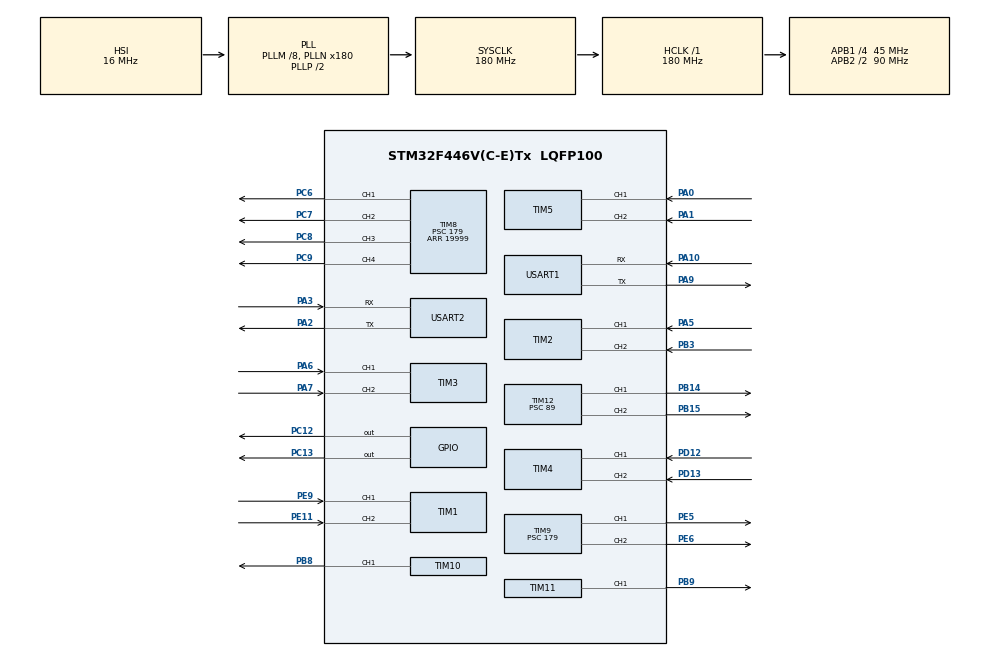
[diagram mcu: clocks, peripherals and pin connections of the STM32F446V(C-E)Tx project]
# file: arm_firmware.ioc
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Dma.Request0=USART1_RX
Dma.USART1_RX.0.Direction=DMA_PERIPH_TO_MEMORY
Dma.USART1_RX.0.FIFOMode=DMA_FIFOMODE_DISABLE
Dma.USART1_RX.0.Instance=DMA2_Stream2
Dma.USART1_RX.0.MemDataAlignment=DMA_MDATAALIGN_BYTE
Dma.USART1_RX.0.MemInc=DMA_MINC_ENABLE
Dma.USART1_RX.0.Mode=DMA_CIRCULAR
Dma.USART1_RX.0.PeriphDataAlignment=DMA_PDATAALIGN_BYTE
Dma.USART1_RX.0.PeriphInc=DMA_PINC_DISABLE
Dma.USART1_RX.0.Priority=DMA_PRIORITY_LOW
Mcu.Family=STM32F4
Mcu.Name=STM32F446V(C-E)Tx
Mcu.Package=LQFP100
NVIC.DMA2_Stream2_IRQn=true\:0\:0\:false\:false\:true\:false\:true\:true
NVIC.PriorityGroup=NVIC_PRIORITYGROUP_4
NVIC.USART1_IRQn=true\:0\:0\:false\:false\:true\:true\:true\:true
PA0-WKUP.Signal=S_TIM5_CH1
PA1.Signal=S_TIM5_CH2
PA10.Mode=Asynchronous
PA10.Signal=USART1_RX
PA13.Mode=Serial_Wire
PA13.Signal=SYS_JTMS-SWDIO
PA14.Mode=Serial_Wire
PA14.Signal=SYS_JTCK-SWCLK
PA2.Mode=Asynchronous
PA2.Signal=USART2_TX
PA3.Mode=Asynchronous
PA3.Signal=USART2_RX
PA5.Signal=S_TIM2_CH1_ETR
PA6.Signal=S_TIM3_CH1
PA7.Signal=S_TIM3_CH2
PA9.Mode=Asynchronous
PA9.Signal=USART1_TX
PB14.Signal=S_TIM12_CH1
PB15.Signal=S_TIM12_CH2
PB3.Signal=S_TIM2_CH2
PB8.Signal=S_TIM10_CH1
PB9.Signal=S_TIM11_CH1
PC12.Signal=GPIO_Output
PC13.Signal=GPIO_Output
PC6.Signal=S_TIM8_CH1
PC7.Signal=S_TIM8_CH2
PC8.Signal=S_TIM8_CH3
PC9.Signal=S_TIM8_CH4
PD12.Signal=S_TIM4_CH1
PD13.Signal=S_TIM4_CH2
PE11.Signal=S_TIM1_CH2
PE5.Signal=S_TIM9_CH1
PE6.Signal=S_TIM9_CH2
PE9.Signal=S_TIM1_CH1
PH0-OSC_IN.Mode=HSE-External-Oscillator
PH0-OSC_IN.Signal=RCC_OSC_IN
PH1-OSC_OUT.Mode=HSE-External-Oscillator
PH1-OSC_OUT.Signal=RCC_OSC_OUT
ProjectManager.HeapSize=0x200
ProjectManager.StackSize=0x400
ProjectManager.TargetToolchain=STM32CubeIDE
RCC.AHBFreq_Value=180000000
RCC.APB1CLKDivider=RCC_HCLK_DIV4
RCC.APB1Freq_Value=45000000
RCC.APB1TimFreq_Value=90000000
RCC.APB2CLKDivider=RCC_HCLK_DIV2
RCC.APB2Freq_Value=90000000
RCC.APB2TimFreq_Value=180000000
RCC.CortexFreq_Value=180000000
RCC.HCLKFreq_Value=180000000
RCC.PLLM=8
RCC.PLLN=180
RCC.SYSCLKFreq_VALUE=180000000
RCC.SYSCLKSource=RCC_SYSCLKSOURCE_PLLCLK
RCC.USBFreq_Value=180000000
RCC.VCOOutputFreq_Value=360000000
SH.S_TIM10_CH1.0=TIM10_CH1,PWM Generation1 CH1
SH.S_TIM11_CH1.0=TIM11_CH1,PWM Generation1 CH1
SH.S_TIM12_CH1.0=TIM12_CH1,PWM Generation1 CH1
SH.S_TIM12_CH2.0=TIM12_CH2,PWM Generation2 CH2
SH.S_TIM1_CH1.0=TIM1_CH1,Encoder_Interface
SH.S_TIM1_CH2.0=TIM1_CH2,Encoder_Interface
SH.S_TIM2_CH1_ETR.0=TIM2_CH1,Encoder_Interface
SH.S_TIM2_CH2.0=TIM2_CH2,Encoder_Interface
SH.S_TIM3_CH1.0=TIM3_CH1,Encoder_Interface
SH.S_TIM3_CH2.0=TIM3_CH2,Encoder_Interface
SH.S_TIM4_CH1.0=TIM4_CH1,Encoder_Interface
SH.S_TIM4_CH2.0=TIM4_CH2,Encoder_Interface
SH.S_TIM5_CH1.0=TIM5_CH1,Encoder_Interface
SH.S_TIM5_CH2.0=TIM5_CH2,Encoder_Interface
SH.S_TIM8_CH1.0=TIM8_CH1,PWM Generation1 CH1
SH.S_TIM8_CH2.0=TIM8_CH2,PWM Generation2 CH2
SH.S_TIM8_CH3.0=TIM8_CH3,PWM Generation3 CH3
SH.S_TIM8_CH4.0=TIM8_CH4,PWM Generation4 CH4
SH.S_TIM9_CH1.0=TIM9_CH1,PWM Generation1 CH1
SH.S_TIM9_CH2.0=TIM9_CH2,PWM Generation2 CH2
TIM1.EncoderMode=TIM_ENCODERMODE_TI12
TIM1.IC1Filter=8
TIM1.IC1Polarity=TIM_ICPOLARITY_FALLING
TIM1.IC2Filter=8
TIM10.Channel=TIM_CHANNEL_1
TIM10.Period=19999
TIM10.Prescaler=179
TIM11.Channel=TIM_CHANNEL_1
TIM11.Period=19999
TIM11.Prescaler=179
TIM12.Channel-PWM\ Generation1\ CH1=TIM_CHANNEL_1
TIM12.Channel-PWM\ Generation2\ CH2=TIM_CHANNEL_2
TIM12.Period=19999
TIM12.Prescaler=89
TIM2.EncoderMode=TIM_ENCODERMODE_TI12
TIM2.IC1Filter=8
TIM2.IC1Polarity=TIM_ICPOLARITY_FALLING
TIM2.IC2Filter=8
TIM3.EncoderMode=TIM_ENCODERMODE_TI12
TIM3.IC1Filter=8
TIM3.IC1Polarity=TIM_ICPOLARITY_FALLING
TIM3.IC2Filter=8
TIM4.EncoderMode=TIM_ENCODERMODE_TI12
TIM4.IC1Filter=8
TIM4.IC1Polarity=TIM_ICPOLARITY_FALLING
TIM4.IC2Filter=8
TIM5.EncoderMode=TIM_ENCODERMODE_TI12
TIM5.IC1Filter=8
TIM5.IC1Polarity=TIM_ICPOLARITY_FALLING
TIM5.IC2Filter=8
TIM8.Channel-PWM\ Generation1\ CH1=TIM_CHANNEL_1
TIM8.Channel-PWM\ Generation2\ CH2=TIM_CHANNEL_2
TIM8.Channel-PWM\ Generation3\ CH3=TIM_CHANNEL_3
TIM8.Channel-PWM\ Generation4\ CH4=TIM_CHANNEL_4
TIM8.Period=19999
TIM8.Prescaler=179
TIM9.Channel-PWM\ Generation1\ CH1=TIM_CHANNEL_1
TIM9.Channel-PWM\ Generation2\ CH2=TIM_CHANNEL_2
TIM9.Period=19999
TIM9.Prescaler=179
USART1.VirtualMode=VM_ASYNC
USART2.VirtualMode=VM_ASYNC
VP_TIM10_VS_ClockSourceINT.Mode=Enable_Timer
VP_TIM11_VS_ClockSourceINT.Mode=Enable_Timer
board=custom

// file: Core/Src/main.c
/* USER CODE BEGIN Header */
/**
  ******************************************************************************
  * @file           : main.c
  * @brief          : Main program body
  ******************************************************************************
  * @attention
  *
  * Copyright (c) 2026 STMicroelectronics.
  * All rights reserved.
  *
  * This software is licensed under terms that can be found in the LICENSE file
  * in the root directory of this software component.
  * If no LICENSE file comes with this software, it is provided AS-IS.
  *
  ******************************************************************************
  */
/* USER CODE END Header */
#include "main.h"

/* USER CODE BEGIN Includes */
#include "servo.h"
#include "encoder.h"
#include "pid.h"
#include "joint_control.h"
/* USER CODE END Includes */

TIM_HandleTypeDef htim1;
TIM_HandleTypeDef htim2;
TIM_HandleTypeDef htim3;
TIM_HandleTypeDef htim4;
TIM_HandleTypeDef htim5;
TIM_HandleTypeDef htim8;
TIM_HandleTypeDef htim9;
TIM_HandleTypeDef htim10;
TIM_HandleTypeDef htim11;
TIM_HandleTypeDef htim12;

UART_HandleTypeDef huart1;
UART_HandleTypeDef huart2;
DMA_HandleTypeDef hdma_usart1_rx;

void SystemClock_Config(void);
static void MX_GPIO_Init(void);
static void MX_DMA_Init(void);
static void MX_TIM1_Init(void);
static void MX_TIM2_Init(void);
static void MX_TIM3_Init(void);
static void MX_TIM4_Init(void);
static void MX_TIM5_Init(void);
static void MX_TIM8_Init(void);
static void MX_TIM9_Init(void);
static void MX_TIM12_Init(void);
static void MX_TIM10_Init(void);
static void MX_TIM11_Init(void);
static void MX_USART1_UART_Init(void);
static void MX_USART2_UART_Init(void);

int main(void)
{

  /* MCU Configuration--------------------------------------------------------*/

  /* Reset of all peripherals, Initializes the Flash interface and the Systick. */
  HAL_Init();

  /* Configure the system clock */
  SystemClock_Config();

  /* Initialize all configured peripherals */
  MX_GPIO_Init();
  MX_DMA_Init();
  MX_TIM1_Init();
  MX_TIM2_Init();
  MX_TIM3_Init();
  MX_TIM4_Init();
  MX_TIM5_Init();
  MX_TIM8_Init();
  MX_TIM9_Init();
  MX_TIM12_Init();
  MX_TIM10_Init();
  MX_TIM11_Init();
  MX_USART1_UART_Init();
  MX_USART2_UART_Init();
  /* USER CODE BEGIN 2 */
  Servo_Init();
  Encoder_Init();
  JointControl_Init();
  /* USER CODE END 2 */

  /* Infinite loop */
  while (1)
  {

    /* USER CODE BEGIN 3 */
    // JointControl_Update(0.010f);
    HAL_GPIO_TogglePin(GPIOC, GPIO_PIN_12);
    HAL_GPIO_TogglePin(GPIOC, GPIO_PIN_13);
     HAL_Delay(500);

    // Call test pattern for PWM output testing
//    Servo_Test_Patterns();
  }
  /* USER CODE END 3 */
}

void SystemClock_Config(void)
{
  RCC_OscInitTypeDef RCC_OscInitStruct = {0};
  RCC_ClkInitTypeDef RCC_ClkInitStruct = {0};

  /** Configure the main internal regulator output voltage
  */
  __HAL_RCC_PWR_CLK_ENABLE();
  __HAL_PWR_VOLTAGESCALING_CONFIG(PWR_REGULATOR_VOLTAGE_SCALE1);

  /** Initializes the RCC Oscillators according to the specified parameters
  * in the RCC_OscInitTypeDef structure.
  */
  RCC_OscInitStruct.OscillatorType = RCC_OSCILLATORTYPE_HSI;
  RCC_OscInitStruct.HSIState = RCC_HSI_ON;
  RCC_OscInitStruct.HSICalibrationValue = RCC_HSICALIBRATION_DEFAULT;
  RCC_OscInitStruct.PLL.PLLState = RCC_PLL_ON;
  RCC_OscInitStruct.PLL.PLLSource = RCC_PLLSOURCE_HSI;
  RCC_OscInitStruct.PLL.PLLM = 8;
  RCC_OscInitStruct.PLL.PLLN = 180;
  RCC_OscInitStruct.PLL.PLLP = RCC_PLLP_DIV2;
  RCC_OscInitStruct.PLL.PLLQ = 2;
  RCC_OscInitStruct.PLL.PLLR = 2;
  if (HAL_RCC_OscConfig(&RCC_OscInitStruct) != HAL_OK)
  {
    Error_Handler();
  }

  /** Activate the Over-Drive mode
  */
  if (HAL_PWREx_EnableOverDrive() != HAL_OK)
  {
    Error_Handler();
  }

  /** Initializes the CPU, AHB and APB buses clocks
  */
  RCC_ClkInitStruct.ClockType = RCC_CLOCKTYPE_HCLK|RCC_CLOCKTYPE_SYSCLK
                              |RCC_CLOCKTYPE_PCLK1|RCC_CLOCKTYPE_PCLK2;
  RCC_ClkInitStruct.SYSCLKSource = RCC_SYSCLKSOURCE_PLLCLK;
  RCC_ClkInitStruct.AHBCLKDivider = RCC_SYSCLK_DIV1;
  RCC_ClkInitStruct.APB1CLKDivider = RCC_HCLK_DIV4;
  RCC_ClkInitStruct.APB2CLKDivider = RCC_HCLK_DIV2;

  if (HAL_RCC_ClockConfig(&RCC_ClkInitStruct, FLASH_LATENCY_5) != HAL_OK)
  {
    Error_Handler();
  }
}

static void MX_TIM1_Init(void)
{

  TIM_Encoder_InitTypeDef sConfig = {0};
  TIM_MasterConfigTypeDef sMasterConfig = {0};

  htim1.Instance = TIM1;
  htim1.Init.Prescaler = 0;
  htim1.Init.CounterMode = TIM_COUNTERMODE_UP;
  htim1.Init.Period = 65535;
  htim1.Init.ClockDivision = TIM_CLOCKDIVISION_DIV1;
  htim1.Init.RepetitionCounter = 0;
  htim1.Init.AutoReloadPreload = TIM_AUTORELOAD_PRELOAD_DISABLE;
  sConfig.EncoderMode = TIM_ENCODERMODE_TI12;
  sConfig.IC1Polarity = TIM_ICPOLARITY_FALLING;
  sConfig.IC1Selection = TIM_ICSELECTION_DIRECTTI;
  sConfig.IC1Prescaler = TIM_ICPSC_DIV1;
  sConfig.IC1Filter = 8;
  sConfig.IC2Polarity = TIM_ICPOLARITY_RISING;
  sConfig.IC2Selection = TIM_ICSELECTION_DIRECTTI;
  sConfig.IC2Prescaler = TIM_ICPSC_DIV1;
  sConfig.IC2Filter = 8;
  if (HAL_TIM_Encoder_Init(&htim1, &sConfig) != HAL_OK)
  {
    Error_Handler();
  }
  sMasterConfig.MasterOutputTrigger = TIM_TRGO_RESET;
  sMasterConfig.MasterSlaveMode = TIM_MASTERSLAVEMODE_DISABLE;
  if (HAL_TIMEx_MasterConfigSynchronization(&htim1, &sMasterConfig) != HAL_OK)
  {
    Error_Handler();
  }

}

static void MX_TIM2_Init(void)
{

  TIM_Encoder_InitTypeDef sConfig = {0};
  TIM_MasterConfigTypeDef sMasterConfig = {0};

  htim2.Instance = TIM2;
  htim2.Init.Prescaler = 0;
  htim2.Init.CounterMode = TIM_COUNTERMODE_UP;
  htim2.Init.Period = 4294967295;
  htim2.Init.ClockDivision = TIM_CLOCKDIVISION_DIV1;
  htim2.Init.AutoReloadPreload = TIM_AUTORELOAD_PRELOAD_DISABLE;
  sConfig.EncoderMode = TIM_ENCODERMODE_TI12;
  sConfig.IC1Polarity = TIM_ICPOLARITY_FALLING;
  sConfig.IC1Selection = TIM_ICSELECTION_DIRECTTI;
  sConfig.IC1Prescaler = TIM_ICPSC_DIV1;
  sConfig.IC1Filter = 8;
  sConfig.IC2Polarity = TIM_ICPOLARITY_RISING;
  sConfig.IC2Selection = TIM_ICSELECTION_DIRECTTI;
  sConfig.IC2Prescaler = TIM_ICPSC_DIV1;
  sConfig.IC2Filter = 8;
  if (HAL_TIM_Encoder_Init(&htim2, &sConfig) != HAL_OK)
  {
    Error_Handler();
  }
  sMasterConfig.MasterOutputTrigger = TIM_TRGO_RESET;
  sMasterConfig.MasterSlaveMode = TIM_MASTERSLAVEMODE_DISABLE;
  if (HAL_TIMEx_MasterConfigSynchronization(&htim2, &sMasterConfig) != HAL_OK)
  {
    Error_Handler();
  }

}

static void MX_TIM3_Init(void)
{

  TIM_Encoder_InitTypeDef sConfig = {0};
  TIM_MasterConfigTypeDef sMasterConfig = {0};

  htim3.Instance = TIM3;
  htim3.Init.Prescaler = 0;
  htim3.Init.CounterMode = TIM_COUNTERMODE_UP;
  htim3.Init.Period = 65535;
  htim3.Init.ClockDivision = TIM_CLOCKDIVISION_DIV1;
  htim3.Init.AutoReloadPreload = TIM_AUTORELOAD_PRELOAD_DISABLE;
  sConfig.EncoderMode = TIM_ENCODERMODE_TI12;
  sConfig.IC1Polarity = TIM_ICPOLARITY_FALLING;
  sConfig.IC1Selection = TIM_ICSELECTION_DIRECTTI;
  sConfig.IC1Prescaler = TIM_ICPSC_DIV1;
  sConfig.IC1Filter = 8;
  sConfig.IC2Polarity = TIM_ICPOLARITY_RISING;
  sConfig.IC2Selection = TIM_ICSELECTION_DIRECTTI;
  sConfig.IC2Prescaler = TIM_ICPSC_DIV1;
  sConfig.IC2Filter = 8;
  if (HAL_TIM_Encoder_Init(&htim3, &sConfig) != HAL_OK)
  {
    Error_Handler();
  }
  sMasterConfig.MasterOutputTrigger = TIM_TRGO_RESET;
  sMasterConfig.MasterSlaveMode = TIM_MASTERSLAVEMODE_DISABLE;
  if (HAL_TIMEx_MasterConfigSynchronization(&htim3, &sMasterConfig) != HAL_OK)
  {
    Error_Handler();
  }

}

static void MX_TIM4_Init(void)
{

  TIM_Encoder_InitTypeDef sConfig = {0};
  TIM_MasterConfigTypeDef sMasterConfig = {0};

  htim4.Instance = TIM4;
  htim4.Init.Prescaler = 0;
  htim4.Init.CounterMode = TIM_COUNTERMODE_UP;
  htim4.Init.Period = 65535;
  htim4.Init.ClockDivision = TIM_CLOCKDIVISION_DIV1;
  htim4.Init.AutoReloadPreload = TIM_AUTORELOAD_PRELOAD_DISABLE;
  sConfig.EncoderMode = TIM_ENCODERMODE_TI12;
  sConfig.IC1Polarity = TIM_ICPOLARITY_FALLING;
  sConfig.IC1Selection = TIM_ICSELECTION_DIRECTTI;
  sConfig.IC1Prescaler = TIM_ICPSC_DIV1;
  sConfig.IC1Filter = 8;
  sConfig.IC2Polarity = TIM_ICPOLARITY_RISING;
  sConfig.IC2Selection = TIM_ICSELECTION_DIRECTTI;
  sConfig.IC2Prescaler = TIM_ICPSC_DIV1;
  sConfig.IC2Filter = 8;
  if (HAL_TIM_Encoder_Init(&htim4, &sConfig) != HAL_OK)
  {
    Error_Handler();
  }
  sMasterConfig.MasterOutputTrigger = TIM_TRGO_RESET;
  sMasterConfig.MasterSlaveMode = TIM_MASTERSLAVEMODE_DISABLE;
  if (HAL_TIMEx_MasterConfigSynchronization(&htim4, &sMasterConfig) != HAL_OK)
  {
    Error_Handler();
  }

}

static void MX_TIM5_Init(void)
{

  TIM_Encoder_InitTypeDef sConfig = {0};
  TIM_MasterConfigTypeDef sMasterConfig = {0};

  htim5.Instance = TIM5;
  htim5.Init.Prescaler = 0;
  htim5.Init.CounterMode = TIM_COUNTERMODE_UP;
  htim5.Init.Period = 4294967295;
  htim5.Init.ClockDivision = TIM_CLOCKDIVISION_DIV1;
  htim5.Init.AutoReloadPreload = TIM_AUTORELOAD_PRELOAD_DISABLE;
  sConfig.EncoderMode = TIM_ENCODERMODE_TI12;
  sConfig.IC1Polarity = TIM_ICPOLARITY_FALLING;
  sConfig.IC1Selection = TIM_ICSELECTION_DIRECTTI;
  sConfig.IC1Prescaler = TIM_ICPSC_DIV1;
  sConfig.IC1Filter = 8;
  sConfig.IC2Polarity = TIM_ICPOLARITY_RISING;
  sConfig.IC2Selection = TIM_ICSELECTION_DIRECTTI;
  sConfig.IC2Prescaler = TIM_ICPSC_DIV1;
  sConfig.IC2Filter = 8;
  if (HAL_TIM_Encoder_Init(&htim5, &sConfig) != HAL_OK)
  {
    Error_Handler();
  }
  sMasterConfig.MasterOutputTrigger = TIM_TRGO_RESET;
  sMasterConfig.MasterSlaveMode = TIM_MASTERSLAVEMODE_DISABLE;
  if (HAL_TIMEx_MasterConfigSynchronization(&htim5, &sMasterConfig) != HAL_OK)
  {
    Error_Handler();
  }

}

static void MX_TIM8_Init(void)
{

  TIM_MasterConfigTypeDef sMasterConfig = {0};
  TIM_OC_InitTypeDef sConfigOC = {0};
  TIM_BreakDeadTimeConfigTypeDef sBreakDeadTimeConfig = {0};

  htim8.Instance = TIM8;
  htim8.Init.Prescaler = 179;
  htim8.Init.CounterMode = TIM_COUNTERMODE_UP;
  htim8.Init.Period = 19999;
  htim8.Init.ClockDivision = TIM_CLOCKDIVISION_DIV1;
  htim8.Init.RepetitionCounter = 0;
  htim8.Init.AutoReloadPreload = TIM_AUTORELOAD_PRELOAD_DISABLE;
  if (HAL_TIM_PWM_Init(&htim8) != HAL_OK)
  {
    Error_Handler();
  }
  sMasterConfig.MasterOutputTrigger = TIM_TRGO_RESET;
  sMasterConfig.MasterSlaveMode = TIM_MASTERSLAVEMODE_DISABLE;
  if (HAL_TIMEx_MasterConfigSynchronization(&htim8, &sMasterConfig) != HAL_OK)
  {
    Error_Handler();
  }
  sConfigOC.OCMode = TIM_OCMODE_PWM1;
  sConfigOC.Pulse = 0;
  sConfigOC.OCPolarity = TIM_OCPOLARITY_HIGH;
  sConfigOC.OCNPolarity = TIM_OCNPOLARITY_HIGH;
  sConfigOC.OCFastMode = TIM_OCFAST_DISABLE;
  sConfigOC.OCIdleState = TIM_OCIDLESTATE_RESET;
  sConfigOC.OCNIdleState = TIM_OCNIDLESTATE_RESET;
  if (HAL_TIM_PWM_ConfigChannel(&htim8, &sConfigOC, TIM_CHANNEL_1) != HAL_OK)
  {
    Error_Handler();
  }
  if (HAL_TIM_PWM_ConfigChannel(&htim8, &sConfigOC, TIM_CHANNEL_2) != HAL_OK)
  {
    Error_Handler();
  }
  if (HAL_TIM_PWM_ConfigChannel(&htim8, &sConfigOC, TIM_CHANNEL_3) != HAL_OK)
  {
    Error_Handler();
  }
  if (HAL_TIM_PWM_ConfigChannel(&htim8, &sConfigOC, TIM_CHANNEL_4) != HAL_OK)
  {
    Error_Handler();
  }
  sBreakDeadTimeConfig.OffStateRunMode = TIM_OSSR_DISABLE;
  sBreakDeadTimeConfig.OffStateIDLEMode = TIM_OSSI_DISABLE;
  sBreakDeadTimeConfig.LockLevel = TIM_LOCKLEVEL_OFF;
  sBreakDeadTimeConfig.DeadTime = 0;
  sBreakDeadTimeConfig.BreakState = TIM_BREAK_DISABLE;
  sBreakDeadTimeConfig.BreakPolarity = TIM_BREAKPOLARITY_HIGH;
  sBreakDeadTimeConfig.AutomaticOutput = TIM_AUTOMATICOUTPUT_DISABLE;
  if (HAL_TIMEx_ConfigBreakDeadTime(&htim8, &sBreakDeadTimeConfig) != HAL_OK)
  {
    Error_Handler();
  }
  HAL_TIM_MspPostInit(&htim8);

}

static void MX_TIM9_Init(void)
{

  TIM_OC_InitTypeDef sConfigOC = {0};

  htim9.Instance = TIM9;
  htim9.Init.Prescaler = 179;
  htim9.Init.CounterMode = TIM_COUNTERMODE_UP;
  htim9.Init.Period = 19999;
  htim9.Init.ClockDivision = TIM_CLOCKDIVISION_DIV1;
  htim9.Init.AutoReloadPreload = TIM_AUTORELOAD_PRELOAD_DISABLE;
  if (HAL_TIM_PWM_Init(&htim9) != HAL_OK)
  {
    Error_Handler();
  }
  sConfigOC.OCMode = TIM_OCMODE_PWM1;
  sConfigOC.Pulse = 0;
  sConfigOC.OCPolarity = TIM_OCPOLARITY_HIGH;
  sConfigOC.OCFastMode = TIM_OCFAST_DISABLE;
  if (HAL_TIM_PWM_ConfigChannel(&htim9, &sConfigOC, TIM_CHANNEL_1) != HAL_OK)
  {
    Error_Handler();
  }
  if (HAL_TIM_PWM_ConfigChannel(&htim9, &sConfigOC, TIM_CHANNEL_2) != HAL_OK)
  {
    Error_Handler();
  }
  HAL_TIM_MspPostInit(&htim9);

}

static void MX_TIM10_Init(void)
{

  TIM_OC_InitTypeDef sConfigOC = {0};

  htim10.Instance = TIM10;
  htim10.Init.Prescaler = 179;
  htim10.Init.CounterMode = TIM_COUNTERMODE_UP;
  htim10.Init.Period = 19999;
  htim10.Init.ClockDivision = TIM_CLOCKDIVISION_DIV1;
  htim10.Init.AutoReloadPreload = TIM_AUTORELOAD_PRELOAD_DISABLE;
  if (HAL_TIM_Base_Init(&htim10) != HAL_OK)
  {
    Error_Handler();
  }
  if (HAL_TIM_PWM_Init(&htim10) != HAL_OK)
  {
    Error_Handler();
  }
  sConfigOC.OCMode = TIM_OCMODE_PWM1;
  sConfigOC.Pulse = 0;
  sConfigOC.OCPolarity = TIM_OCPOLARITY_HIGH;
  sConfigOC.OCFastMode = TIM_OCFAST_DISABLE;
  if (HAL_TIM_PWM_ConfigChannel(&htim10, &sConfigOC, TIM_CHANNEL_1) != HAL_OK)
  {
    Error_Handler();
  }
  HAL_TIM_MspPostInit(&htim10);

}

static void MX_TIM11_Init(void)
{

  TIM_OC_InitTypeDef sConfigOC = {0};

  htim11.Instance = TIM11;
  htim11.Init.Prescaler = 179;
  htim11.Init.CounterMode = TIM_COUNTERMODE_UP;
  htim11.Init.Period = 19999;
  htim11.Init.ClockDivision = TIM_CLOCKDIVISION_DIV1;
  htim11.Init.AutoReloadPreload = TIM_AUTORELOAD_PRELOAD_DISABLE;
  if (HAL_TIM_Base_Init(&htim11) != HAL_OK)
  {
    Error_Handler();
  }
  if (HAL_TIM_PWM_Init(&htim11) != HAL_OK)
  {
    Error_Handler();
  }
  sConfigOC.OCMode = TIM_OCMODE_PWM1;
  sConfigOC.Pulse = 0;
  sConfigOC.OCPolarity = TIM_OCPOLARITY_HIGH;
  sConfigOC.OCFastMode = TIM_OCFAST_DISABLE;
  if (HAL_TIM_PWM_ConfigChannel(&htim11, &sConfigOC, TIM_CHANNEL_1) != HAL_OK)
  {
    Error_Handler();
  }
  HAL_TIM_MspPostInit(&htim11);

}

static void MX_TIM12_Init(void)
{

  TIM_OC_InitTypeDef sConfigOC = {0};

  htim12.Instance = TIM12;
  htim12.Init.Prescaler = 89;
  htim12.Init.CounterMode = TIM_COUNTERMODE_UP;
  htim12.Init.Period = 19999;
  htim12.Init.ClockDivision = TIM_CLOCKDIVISION_DIV1;
  htim12.Init.AutoReloadPreload = TIM_AUTORELOAD_PRELOAD_DISABLE;
  if (HAL_TIM_PWM_Init(&htim12) != HAL_OK)
  {
    Error_Handler();
  }
  sConfigOC.OCMode = TIM_OCMODE_PWM1;
  sConfigOC.Pulse = 0;
  sConfigOC.OCPolarity = TIM_OCPOLARITY_HIGH;
  sConfigOC.OCFastMode = TIM_OCFAST_DISABLE;
  if (HAL_TIM_PWM_ConfigChannel(&htim12, &sConfigOC, TIM_CHANNEL_1) != HAL_OK)
  {
    Error_Handler();
  }
  if (HAL_TIM_PWM_ConfigChannel(&htim12, &sConfigOC, TIM_CHANNEL_2) != HAL_OK)
  {
    Error_Handler();
  }
  HAL_TIM_MspPostInit(&htim12);

}

static void MX_USART1_UART_Init(void)
{

  huart1.Instance = USART1;
  huart1.Init.BaudRate = 115200;
  huart1.Init.WordLength = UART_WORDLENGTH_8B;
  huart1.Init.StopBits = UART_STOPBITS_1;
  huart1.Init.Parity = UART_PARITY_NONE;
  huart1.Init.Mode = UART_MODE_TX_RX;
  huart1.Init.HwFlowCtl = UART_HWCONTROL_NONE;
  huart1.Init.OverSampling = UART_OVERSAMPLING_16;
  if (HAL_UART_Init(&huart1) != HAL_OK)
  {
    Error_Handler();
  }

}

static void MX_USART2_UART_Init(void)
{

  huart2.Instance = USART2;
  huart2.Init.BaudRate = 115200;
  huart2.Init.WordLength = UART_WORDLENGTH_8B;
  huart2.Init.StopBits = UART_STOPBITS_1;
  huart2.Init.Parity = UART_PARITY_NONE;
  huart2.Init.Mode = UART_MODE_TX_RX;
  huart2.Init.HwFlowCtl = UART_HWCONTROL_NONE;
  huart2.Init.OverSampling = UART_OVERSAMPLING_16;
  if (HAL_UART_Init(&huart2) != HAL_OK)
  {
    Error_Handler();
  }

}

static void MX_DMA_Init(void)
{

  /* DMA controller clock enable */
  __HAL_RCC_DMA2_CLK_ENABLE();

  /* DMA interrupt init */
  /* DMA2_Stream2_IRQn interrupt configuration */
  HAL_NVIC_SetPriority(DMA2_Stream2_IRQn, 0, 0);
  HAL_NVIC_EnableIRQ(DMA2_Stream2_IRQn);

}

static void MX_GPIO_Init(void)
{
  GPIO_InitTypeDef GPIO_InitStruct = {0};

  /* GPIO Ports Clock Enable */
  __HAL_RCC_GPIOE_CLK_ENABLE();
  __HAL_RCC_GPIOC_CLK_ENABLE();
  __HAL_RCC_GPIOH_CLK_ENABLE();
  __HAL_RCC_GPIOA_CLK_ENABLE();
  __HAL_RCC_GPIOB_CLK_ENABLE();
  __HAL_RCC_GPIOD_CLK_ENABLE();

  /*Configure GPIO pin Output Level */
  HAL_GPIO_WritePin(GPIOC, GPIO_PIN_13|GPIO_PIN_12, GPIO_PIN_RESET);

  /*Configure GPIO pins : PC13 PC12 */
  GPIO_InitStruct.Pin = GPIO_PIN_13|GPIO_PIN_12;
  GPIO_InitStruct.Mode = GPIO_MODE_OUTPUT_PP;
  GPIO_InitStruct.Pull = GPIO_NOPULL;
  GPIO_InitStruct.Speed = GPIO_SPEED_FREQ_LOW;
  HAL_GPIO_Init(GPIOC, &GPIO_InitStruct);

}

void Error_Handler(void)
{
  __disable_irq();
  while (1)
  {
  }
}
